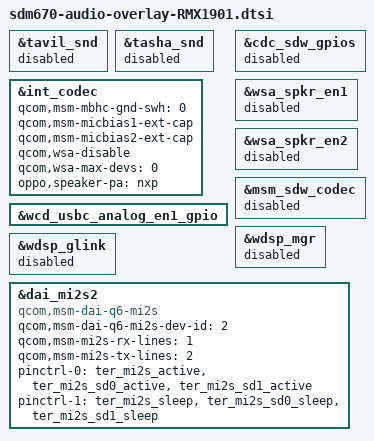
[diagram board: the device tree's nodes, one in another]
&tavil_snd {
    status = "disabled";
};

&tasha_snd {
    status = "disabled";
};

&int_codec {
    qcom,msm-mbhc-gnd-swh = <0>;
    qcom,msm-micbias1-ext-cap;
    qcom,msm-micbias2-ext-cap;
    qcom,wsa-disable;
    qcom,wsa-max-devs = <0>;
    oppo,speaker-pa = "nxp";
    /delete-property/ qcom,wsa-devs;
    /delete-property/ qcom,wsa-aux-dev-prefix;
};

&wcd_usbc_analog_en1_gpio {
    /delete-property/ pinctrl-names;
    /delete-property/ pinctrl-0;
    /delete-property/ pinctrl-1;
};

&cdc_sdw_gpios { 
    status = "disabled";
};

&wsa_spkr_en1 { 
    status = "disabled";
};

&wsa_spkr_en2 {
    status = "disabled";
};

&msm_sdw_codec {
    status = "disabled";
};

&wdsp_mgr {
    status = "disabled";
};

&wdsp_glink {
    status = "disabled";
};

&dai_mi2s2 {
    compatible = "qcom,msm-dai-q6-mi2s";
    qcom,msm-dai-q6-mi2s-dev-id = <2>;
    qcom,msm-mi2s-rx-lines = <1>;
    qcom,msm-mi2s-tx-lines = <2>;
    pinctrl-names = "default", "sleep";
    pinctrl-0 = <&ter_mi2s_active &ter_mi2s_sd0_active &ter_mi2s_sd1_active>;
    pinctrl-1 = <&ter_mi2s_sleep &ter_mi2s_sd0_sleep &ter_mi2s_sd1_sleep>;
};
